AUTOSAR XML (schema 00046)
package /ComponentTypes
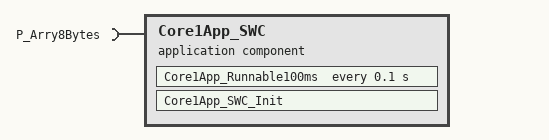
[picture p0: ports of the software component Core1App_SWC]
  application sw component type Core1App_SWC
    require port P_Arry8Bytes: nonqueued-receiver-com-spec{data-element=DEP_Arry8Bytes, init-value=8 x 0}, required-interface=P_Arry8Bytes
    behavior Core1App_SWC_InternalBehavior
      init event Core1App_SWC_InitEvent: start-on-event=Core1App_SWC_Init
      timing event TMT_Core1App_Runnable100ms: start-on-event=Core1App_Runnable100ms, period=0.1
      runnable Core1App_Runnable100ms
        data-receive-point-by-arguments:
          access REC_P_Arry8Bytes_DEP_Arry8Bytes: accessed-variable=P_Arry8Bytes.DEP_Arry8Bytes
      runnable Core1App_SWC_Init
  swc implementation Core1App_SWC_Implementation: behavior=Core1App_SWC_InternalBehavior
